AUTOSAR XML (schema 4-3-0)
standard types defined: uint8, uint8_DataConstr
package /ComponentTypes
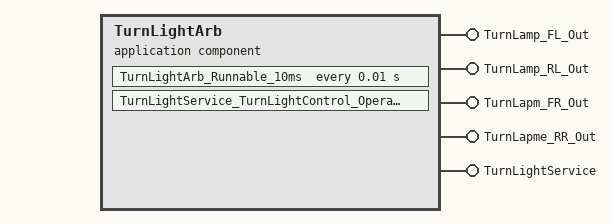
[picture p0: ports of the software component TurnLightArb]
  application sw component type TurnLightArb
    5 x provide port:
      TurnLamp_FL_Out: nonqueued-sender-com-spec{data-element=TurnLamp_FL_Out/u8_Signal, init-value=0}, provided-interface=TurnLamp_FL_Out
      TurnLamp_RL_Out: nonqueued-sender-com-spec{data-element=TurnLamp_RL_Out/u8_Signal, init-value=0}, provided-interface=TurnLamp_RL_Out
      TurnLapm_FR_Out: nonqueued-sender-com-spec{data-element=TurnLapm_FR_Out/u8_Signal, init-value=0}, provided-interface=TurnLapm_FR_Out
      TurnLapme_RR_Out: nonqueued-sender-com-spec{data-element=TurnLapme_RR_Out/u8_Signal, init-value=0}, provided-interface=TurnLapme_RR_Out
      TurnLightService: server-com-spec{operation=TurnLightControl_Operation, queue-length=1}, provided-interface=TurnLightService
    behavior TurnLightArb_InternalBehavior
      timing event TMT_TurnLightArb_Runnable_10ms: start-on-event=TurnLightArb_Runnable_10ms, period=0.01
      operation invoked event OIT_TurnLightService_TurnLightControl_Operation_TurnLightService_TurnLightControl_Operation: start-on-event=TurnLightService_TurnLightControl_Operation, operation=TurnLightService.TurnLightControl_Operation
      runnable TurnLightArb_Runnable_10ms: minimum-start-interval=0.01
        data-send-points:
          4 x access:
            SEND_TurnLamp_FL_Out_u8_Signal: accessed-variable=TurnLamp_FL_Out.u8_Signal
            SEND_TurnLamp_RL_Out_u8_Signal: accessed-variable=TurnLamp_RL_Out.u8_Signal
            SEND_TurnLapm_FR_Out_u8_Signal: accessed-variable=TurnLapm_FR_Out.u8_Signal
            SEND_TurnLapme_RR_Out_u8_Signal: accessed-variable=TurnLapme_RR_Out.u8_Signal
      runnable TurnLightService_TurnLightControl_Operation: can-be-invoked-concurrently=true
  swc implementation TurnLightArb_Implementation: behavior=TurnLightArb_InternalBehavior
    code-descriptors:
      code Default: artifact-descriptors=autosar-engineering-object={short-label=Default, category=SWSRC}
package /DataTypes
  impl type ComplexTurnLightONOFFType: compu {0=NORQEUST, 0=OFF, 0=ON}, implementation-data-type=uint8, type-emitter=RTE
  impl type ComplexTurnLightPositionType: compu-method=ComplexTurnLightPosition, implementation-data-type=uint8, type-emitter=RTE
  impl type TurnLightService: category=STRUCTURE, sw-calibration-access=READ-ONLY, type-emitter=RTE
    7 x element, all with category=TYPE_REFERENCE:
      TurnLightPosition: compu-method=ComplexTurnLightPosition, implementation-data-type=ComplexTurnLightPositionType
      TurnLightOnOff: compu {0=NORQEUST, 0=OFF, 0=ON}, implementation-data-type=ComplexTurnLightONOFFType
      TurnLightDutyCycle: implementation-data-type=uint8, invalid-value=0
      TurnLightCycle: implementation-data-type=uint8, invalid-value=0
      TurnLightTimes: implementation-data-type=uint8, invalid-value=0
      TurnLightNumber: implementation-data-type=uint8, invalid-value=0
      TurnLightPriority: implementation-data-type=uint8, invalid-value=0
package /DataTypes/CompuMethods
  compu method ComplexTurnLightPosition: 0=NOREQUEST, 1=LEFT, 2=RIGHT, 3=ALL, 4=FRONT_LEFT, 5=MIDDLE_LEFT, 6=REAR_LEFT, 7=FRONT_RIGHT, 8=MIDDLE_RIGHT (CompuScale), 9=REAR_RIGHT
package /PortInterfaces
  client server interface TurnLightService
    operation TurnLightControl_Operation
      arg TurnLightCtrlPara: type=TurnLightService, direction=IN, server-argument-impl-policy=USE-ARGUMENT-TYPE
  4 x sender receiver interface:
    TurnLamp_FL_Out: invalidation-policy{data-element=TurnLamp_FL_Out/u8_Signal, handle-invalid=DONT-INVALIDATE}
      data u8_Signal: type=uint8
    TurnLamp_RL_Out: invalidation-policy{data-element=TurnLamp_RL_Out/u8_Signal, handle-invalid=DONT-INVALIDATE}
      data u8_Signal: type=uint8
    TurnLapm_FR_Out: invalidation-policy{data-element=TurnLapm_FR_Out/u8_Signal, handle-invalid=DONT-INVALIDATE}
      data u8_Signal: type=uint8
    TurnLapme_RR_Out: invalidation-policy{data-element=TurnLapme_RR_Out/u8_Signal, handle-invalid=DONT-INVALIDATE}
      data u8_Signal: type=uint8
